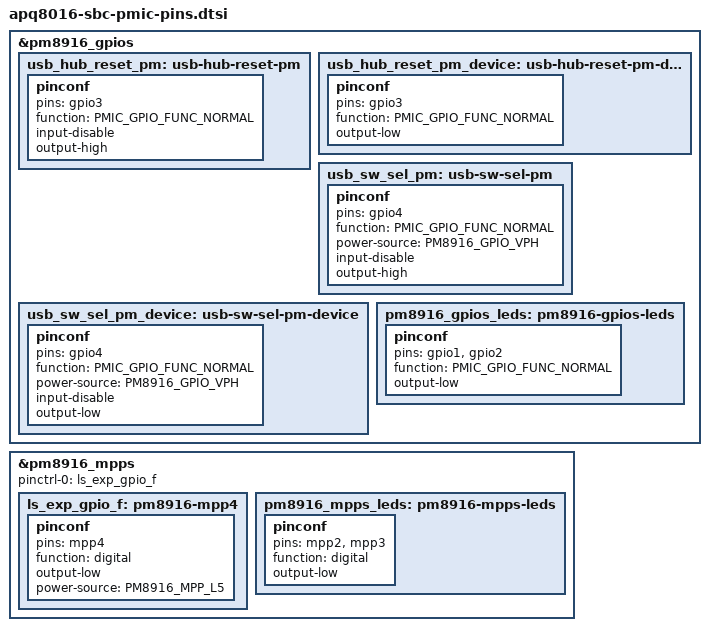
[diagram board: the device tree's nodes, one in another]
// SPDX-License-Identifier: GPL-2.0
#include <dt-bindings/pinctrl/qcom,pmic-gpio.h>
#include <dt-bindings/pinctrl/qcom,pmic-mpp.h>

&pm8916_gpios {

	usb_hub_reset_pm: usb-hub-reset-pm {
		pinconf {
			pins = "gpio3";
			function = PMIC_GPIO_FUNC_NORMAL;
			input-disable;
			output-high;
		};
	};

	usb_hub_reset_pm_device: usb-hub-reset-pm-device {
		pinconf {
			pins = "gpio3";
			function = PMIC_GPIO_FUNC_NORMAL;
			output-low;
		};
	};

	usb_sw_sel_pm: usb-sw-sel-pm {
		pinconf {
			pins = "gpio4";
			function = PMIC_GPIO_FUNC_NORMAL;
			power-source = <PM8916_GPIO_VPH>;
			input-disable;
			output-high;
		};
	};

	usb_sw_sel_pm_device: usb-sw-sel-pm-device {
		pinconf {
			pins = "gpio4";
			function = PMIC_GPIO_FUNC_NORMAL;
			power-source = <PM8916_GPIO_VPH>;
			input-disable;
			output-low;
		};
	};

	pm8916_gpios_leds: pm8916-gpios-leds {
		pinconf {
			pins = "gpio1", "gpio2";
			function = PMIC_GPIO_FUNC_NORMAL;
			output-low;
		};
	};
};

&pm8916_mpps {

	pinctrl-names = "default";
	pinctrl-0 = <&ls_exp_gpio_f>;

	ls_exp_gpio_f: pm8916-mpp4 {
		pinconf {
			pins = "mpp4";
			function = "digital";
			output-low;
			power-source = <PM8916_MPP_L5>;	// 1.8V
		};
	};

	pm8916_mpps_leds: pm8916-mpps-leds {
		pinconf {
			pins = "mpp2", "mpp3";
			function = "digital";
			output-low;
		};
	};
};
